# K1921VK035 register map
Vendor: NIIET; Series: K1921VKx; File version: 2.10
CPU: CM4 r0p1, little endian, MPU, FPU, 3 interrupt priority bits
Registers are 32-bit, read-write, reset 0x0 unless marked. A register's access mark holds for its fields unless they carry their own. Offsets are from the block's base; [hi:lo] are bit positions; lines under a group give offsets from that group; {n}, {i} and the like mark numbered series.

## GPIOA — GPIO control registers
Base 0x40010000
Same registers: GPIOB 0x40011000
0x00 DATA — Data Input register
  [15:0] VAL
0x04 DATAOUT — Data output register
  [15:0] VAL
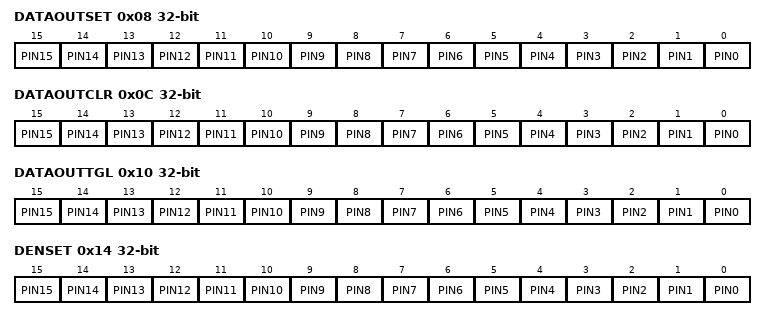
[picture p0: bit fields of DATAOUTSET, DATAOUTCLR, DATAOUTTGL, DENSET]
0x08 DATAOUTSET — Data output set bits register
  [n] PIN{n} (n=0..15) — Data output set bit {n}
0x0C DATAOUTCLR — Data output clear bits register
  [n] PIN{n} (n=0..15) — Data output clear bit {n}
0x10 DATAOUTTGL — Data output toogle bits register
  [n] PIN{n} (n=0..15) — Data output toogle bit {n}
0x14 DENSET — Digital function (PAD) enable register
  [n] PIN{n} (n=0..15) — Digital function (PAD) enable on pin {n}
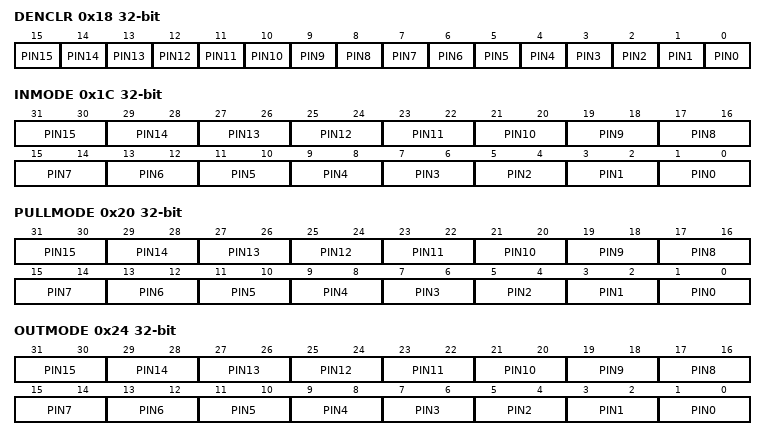
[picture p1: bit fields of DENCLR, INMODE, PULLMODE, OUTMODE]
0x18 DENCLR — Digital function (PAD) disable register
  [n] PIN{n} (n=0..15) — Digital function (PAD) disable on pin {n}
0x1C INMODE — Select input mode register
  [all] fields
    0=Schmitt (Scmitt buffer); 1=CMOS (CMOS buffer); 3=Disable (Input buffer disabled)
  [2n+1:2n] PIN{n} (n=0..15) — Select input mode for pin {n}
0x20 PULLMODE — Select pull mode register
  [all] fields
    0=Disable (Pull disabled); 1=PU (Pull-up); 2=PD (Pull-down)
  [2n+1:2n] PIN{n} (n=0..15) — Select pull mode for pin {n}
0x24 OUTMODE — Select output mode register
  [all] fields
    0=PP (Push-pull output); 1=OD (Open drain output); 2=OS (Open source output)
  [2n+1:2n] PIN{n} (n=0..15) — Select output mode for pin {n}
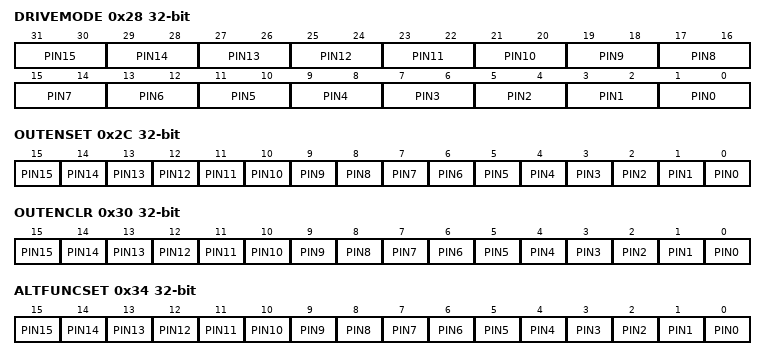
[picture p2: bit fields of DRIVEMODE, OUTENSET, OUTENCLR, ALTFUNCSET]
0x28 DRIVEMODE — Select drive mode register
  [all] fields
    0=HF (High strength and Fast rate); 1=HS (High strength and Slow rate); 2=LF (Low strength and Fast rate); 3=LS (Low strength and Slow rate)
  [2n+1:2n] PIN{n} (n=0..15) — Select drive mode for pin {n}
0x2C OUTENSET — Output enable register
  [n] PIN{n} (n=0..15) — Output enable for pin {n}
0x30 OUTENCLR — Output disable register
  [n] PIN{n} (n=0..15) — Output disable for pin {n}
0x34 ALTFUNCSET — Alternative function enable register
  [n] PIN{n} (n=0..15) — Alternative function enable for pin {n}
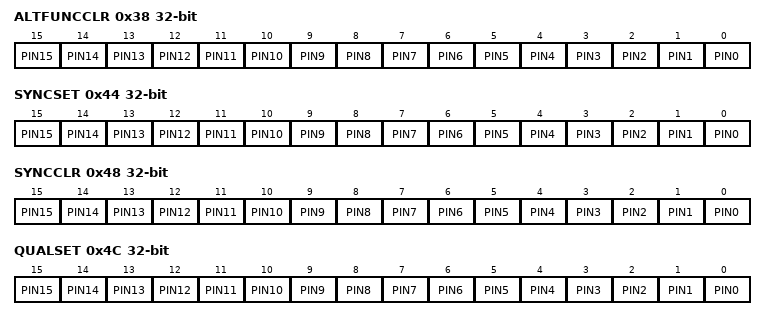
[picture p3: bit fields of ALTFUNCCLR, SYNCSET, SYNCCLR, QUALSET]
0x38 ALTFUNCCLR — Alternative function disable register
  [n] PIN{n} (n=0..15) — Alternative function disable for pin {n}
0x44 SYNCSET — Additional double flip-flop syncronization enable register
  [n] PIN{n} (n=0..15) — Additional double flip-flop syncronization buffer enable for pin {n}
0x48 SYNCCLR — Additional double flip-flop syncronization disable register
  [n] PIN{n} (n=0..15) — Additional double flip-flop syncronization disable for pin {n}
0x4C QUALSET — Qualifier enable register
  [n] PIN{n} (n=0..15) — Qualifier enable for pin {n}
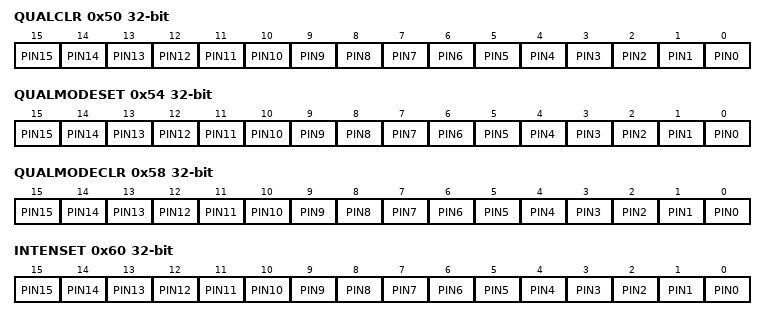
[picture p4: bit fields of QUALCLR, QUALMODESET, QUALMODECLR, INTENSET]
0x50 QUALCLR — Qualifier disable register
  [n] PIN{n} (n=0..15) — Qualifier disable for pin {n}
0x54 QUALMODESET — Qualifier mode set register
  [n] PIN{n} (n=0..15) — Qualifier mode set for pin {n}
0x58 QUALMODECLR — Qualifier mode clear register
  [n] PIN{n} (n=0..15) — Qualifier mode clear for pin {n}
0x5C QUALSAMPLE — Qualifier sample period register
  [7:0] VAL — Qualifier sample period
0x60 INTENSET — Interrupt enable register
  [n] PIN{n} (n=0..15) — Interrupt enable for pin {n}
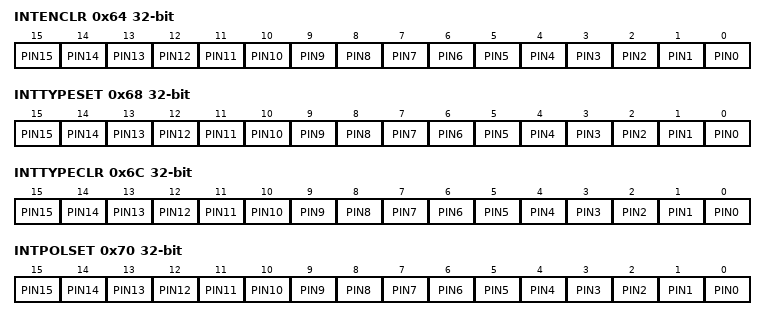
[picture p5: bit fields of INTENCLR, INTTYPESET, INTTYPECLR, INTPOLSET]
0x64 INTENCLR — Interrupt disable register
  [n] PIN{n} (n=0..15) — Interrupt disable for pin {n}
0x68 INTTYPESET — Interrupt type set register
  [n] PIN{n} (n=0..15) — Interrupt type set for pin {n}
0x6C INTTYPECLR — Interrupt type clear register
  [n] PIN{n} (n=0..15) — Interrupt type clear for pin {n}
0x70 INTPOLSET — Interrupt polarity set register
  [n] PIN{n} (n=0..15) — Interrupt polarity set for pin {n}
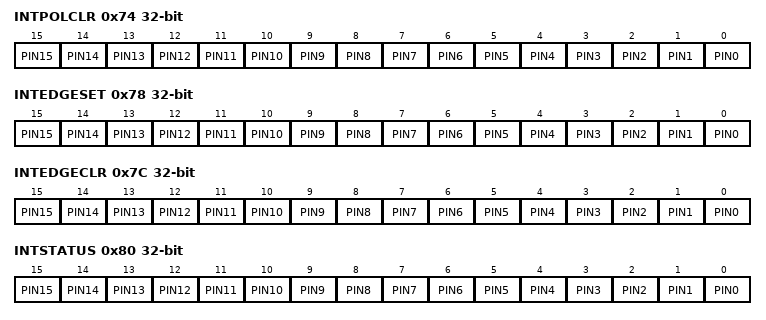
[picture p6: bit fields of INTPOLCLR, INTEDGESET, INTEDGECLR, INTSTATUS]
0x74 INTPOLCLR — Interrupt polarity clear register
  [n] PIN{n} (n=0..15) — Interrupt polarity clear for pin {n}
0x78 INTEDGESET — Interrupt every edge set register
  [n] PIN{n} (n=0..15) — Interrupt every edge set for pin {n}
0x7C INTEDGECLR — Interrupt every edge clear register
  [n] PIN{n} (n=0..15) — Interrupt every edge clear for pin {n}
0x80 INTSTATUS — Interrupt status
  [n] PIN{n} (n=0..15) — Interrupt status of pin {n}
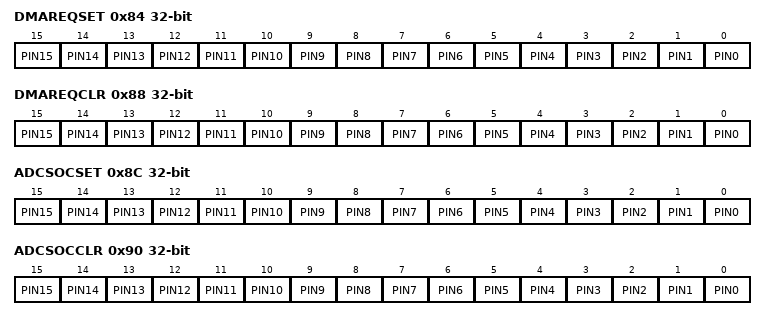
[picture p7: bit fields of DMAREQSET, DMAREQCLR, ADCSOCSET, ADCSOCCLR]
0x84 DMAREQSET — DMA request enable register
  [n] PIN{n} (n=0..15) — DMA request enable for pin {n}
0x88 DMAREQCLR — DMA request disable register
  [n] PIN{n} (n=0..15) — DMA request disable for pin {n}
0x8C ADCSOCSET — ADC Start Of Conversion enable register
  [n] PIN{n} (n=0..15) — ADC SOC enable for pin {n}
0x90 ADCSOCCLR — ADC Start Of Conversion disable register
  [n] PIN{n} (n=0..15) — ADC SOC disable for pin {n}
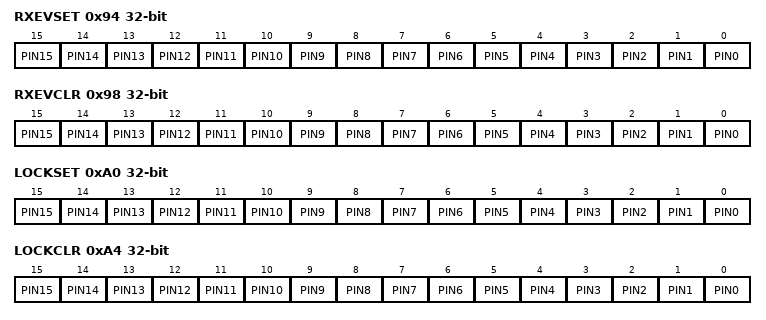
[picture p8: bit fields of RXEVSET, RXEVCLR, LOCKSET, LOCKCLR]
0x94 RXEVSET — Core RXEV request enable register
  [n] PIN{n} (n=0..15) — RXEV enable for pin {n}
0x98 RXEVCLR — Core RXEV request disable register
  [n] PIN{n} (n=0..15) — RXEV disable for pin {n}
0x9C LOCKKEY wo — Key register to unlock LOCKSET/LOCKCLR registers for write (KEY=0xADEADBEE)
  [31:0] VAL — Key to unlock LOCKSET/LOCKCLR registers for write (KEY=0xADEADBEE)
    on write: 0xEEEEEEEE=LOCK (0xEEEEEEEE, key to lock registers); 0xADEADBEE=UNLOCK (0xADEADBEE, key to unlock registers)
0x9C LOCKSTAT ro (alternate view of LOCKKEY) — LOCKSET/LOCKCLR write enable status register
  [0] WREN — LOCKSET/LOCKCLR write enable status
0xA0 LOCKSET — Lock pins configuration enable register
  [n] PIN{n} (n=0..15) — Lock configuration enable for pin {n}
0xA4 LOCKCLR — Lock pins configuration disable register
  [n] PIN{n} (n=0..15) — Lock configuration disable for pin {n}
{0x400+4i} MASKLB[{i}] (i=0..255) group
  0x00 MASKLB — Mask register low byte of port
    [7:0] VAL — Mask low byte
{0x800+4i} MASKHB[{i}] (i=0..255) group
  0x00 MASKHB — Mask register High byte of port
    [15:8] VAL — Mask high byte
